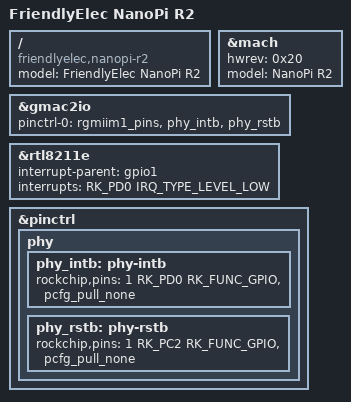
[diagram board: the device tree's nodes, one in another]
/*
 * Copyright (c) 2019 FriendlyElec Computer Tech. Co., Ltd.
 * (http://www.friendlyarm.com)
 *
 * This program is free software; you can redistribute it and/or
 * modify it under the terms of the GNU General Public License
 * as published by the Free Software Foundation; either version 2
 * of the License, or (at your option) any later version.
 *
 * This program is distributed in the hope that it will be useful,
 * but WITHOUT ANY WARRANTY; without even the implied warranty of
 * MERCHANTABILITY or FITNESS FOR A PARTICULAR PURPOSE.  See the
 * GNU General Public License for more details.
 *
 * You should have received a copy of the GNU General Public License
 * along with this program.  If not, see <http://www.gnu.org/licenses/>.
 */

/dts-v1/;
#include "rk3328-nanopi-r2-common.dtsi"

/ {
	model = "FriendlyElec NanoPi R2";
	compatible = "friendlyelec,nanopi-r2", "rockchip,rk3328";
};

&mach {
	hwrev = <0x20>;
	model = "NanoPi R2";
};

&gmac2io {
	pinctrl-0 = <&rgmiim1_pins>, <&phy_intb>, <&phy_rstb>;
};

&rtl8211e {
	interrupt-parent = <&gpio1>;
	interrupts = <RK_PD0 IRQ_TYPE_LEVEL_LOW>;
};

&pinctrl {
	phy {
		phy_intb: phy-intb {
			rockchip,pins = <1 RK_PD0 RK_FUNC_GPIO &pcfg_pull_none>;
		};

		phy_rstb: phy-rstb {
			rockchip,pins = <1 RK_PC2 RK_FUNC_GPIO &pcfg_pull_none>;
		};
	};
};
